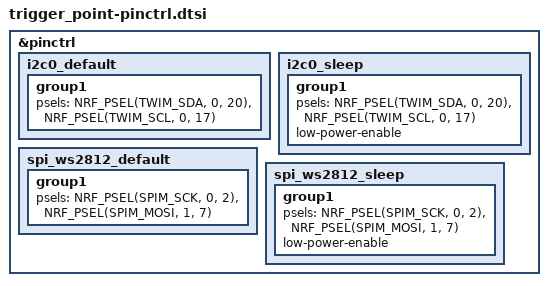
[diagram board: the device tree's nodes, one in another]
#include <zephyr/dt-bindings/pinctrl/nrf-pinctrl.h>

/* Pinctrl for I2C0 and SPI timing (WS2812) */
&pinctrl {
    i2c0_default: i2c0_default {
        group1 {
            psels = <NRF_PSEL(TWIM_SDA, 0, 20)>,
                    <NRF_PSEL(TWIM_SCL, 0, 17)>;
        };
    };

    i2c0_sleep: i2c0_sleep {
        group1 {
            psels = <NRF_PSEL(TWIM_SDA, 0, 20)>,
                    <NRF_PSEL(TWIM_SCL, 0, 17)>;
            low-power-enable;
        };
    };

    /* EXACT label the dtsi references */
    spi_ws2812_default: spi_ws2812_default {
        group1 {
            /* MOSI = P1.07 (data), SCK = P0.02 (dummy) */
            psels = <NRF_PSEL(SPIM_SCK,  0, 2)>,
                    <NRF_PSEL(SPIM_MOSI, 1, 7)>;
        };
    };
        spi_ws2812_sleep: spi_ws2812_sleep {
            group1 { 
                psels = <NRF_PSEL(SPIM_SCK, 0, 2)>,
                        <NRF_PSEL(SPIM_MOSI, 1, 7)>;
                        low-power-enable; };
    };
};
